# f29h85x_sent_mtpg_regs register map
Vendor: Texas Instruments
Peripheral module from a debugger description file (folder C29).
Registers are 32-bit, access per field, no defined reset value unless marked. A register's access mark holds for its fields unless they carry their own. Offsets are as the file gives them; lines under a group give offsets from that group; [hi:lo] are bit positions; {n}, {i} and the like mark numbered series; 'fields as' and 'values as' point back to an identical list; <NAME> marks a mode.

## SENT_MTPG — SENT MTPG Registers
0x00 BC_MTP_EN
  [0] MTP_EN rw
{0x0+4i} BC_MTP_CMP{i} (i=1..9)
  [10:0] TOGGLETIME rw
0x2C BC_MTP_PERIOD
  [10:0] PERIOD rw
0x34 BC_TRIGSEL
  [6:0] TRIGSEL rw
0x38 BC_MTP_SWTR rw
  [0] SWTR
{0x0+0x100*i} S{i}_MTP_EN (i=1..4)
  [0] MTP_EN rw
{0x100+4i} S1_MTP_CMP{i} (i=1..9)
  [10:0] TOGGLETIME rw
{0x28+0x100*i} S{i}_MTP_CMP10RE (i=1..4)
  [10:0] TOGGLETIME rw
{0x2C+0x100*i} S{i}_MTP_PERIOD (i=1..4)
  [10:0] PERIOD rw
{0x30+0x100*i} S{i}_MTP_TO rw (i=1..4)
  [31:0] TIMEOUT
{0x34+0x100*i} S{i}_TRIGSEL (i=1..4)
  [6:0] TRIGSEL rw
{0x38+0x100*i} S{i}_MTP_SWTR rw (i=1..4)
  [0] SWTR
{0x200+4i} S2_MTP_CMP{i} (i=1..9)
  [10:0] TOGGLETIME rw
{0x300+4i} S3_MTP_CMP{i} (i=1..9)
  [10:0] TOGGLETIME rw
{0x400+4i} S4_MTP_CMP{i} (i=1..9)
  [10:0] TOGGLETIME rw
0x700 WAITTIME
  [15:0] WAITTIME rw
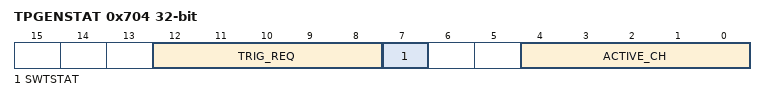
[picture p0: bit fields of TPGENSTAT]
0x704 TPGENSTAT ro
  [12:8] TRIG_REQ, [7] SWTSTAT, [4:0] ACTIVE_CH
0x730 MTP_VERSION ro
0x73C MTP_SWR rw
  [0] SWR
